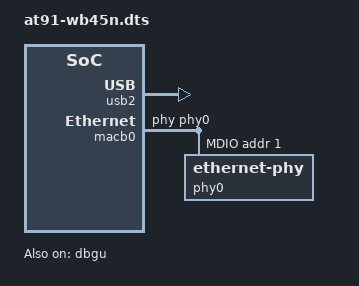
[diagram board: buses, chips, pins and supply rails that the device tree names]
// SPDX-License-Identifier: LicenseRef-Ezurio-Clause
/*
 * at91-wb45n.dts - Device Tree file for WB45NBT board
 *
 * Copyright (C) 2020 Ezurio
 */

/dts-v1/;

#include "at91-wb45n.dtsi"

&usb2 {
	status = "okay";
};

&macb0 {
	status = "okay";

	phy-handle = <&phy0>;

	mdio {
		#address-cells = <1>;
		#size-cells = <0>;

		phy0: ethernet-phy@1 {
			reg = <1>;
		};
	};
};

&dbgu {
	status = "okay";
};
